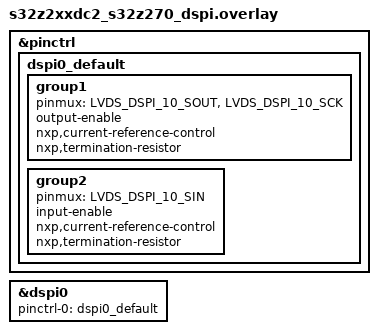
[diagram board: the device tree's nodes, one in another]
/*
 * Copyright 2024 NXP
 *
 * SPDX-License-Identifier: Apache-2.0
 */

&pinctrl {
	dspi0_default: dspi0_default {
		group1 {
			pinmux = <LVDS_DSPI_10_SOUT>, <LVDS_DSPI_10_SCK>;
			output-enable;
			nxp,current-reference-control;
			nxp,termination-resistor;
		};

		group2 {
			pinmux = <LVDS_DSPI_10_SIN>;
			input-enable;
			nxp,current-reference-control;
			nxp,termination-resistor;
		};
	};
};

spi_loopback: &dspi0 {
	pinctrl-0 = <&dspi0_default>;
	pinctrl-names = "default";
	status = "okay";
};

#include "../spi-loopback.dtsi"
